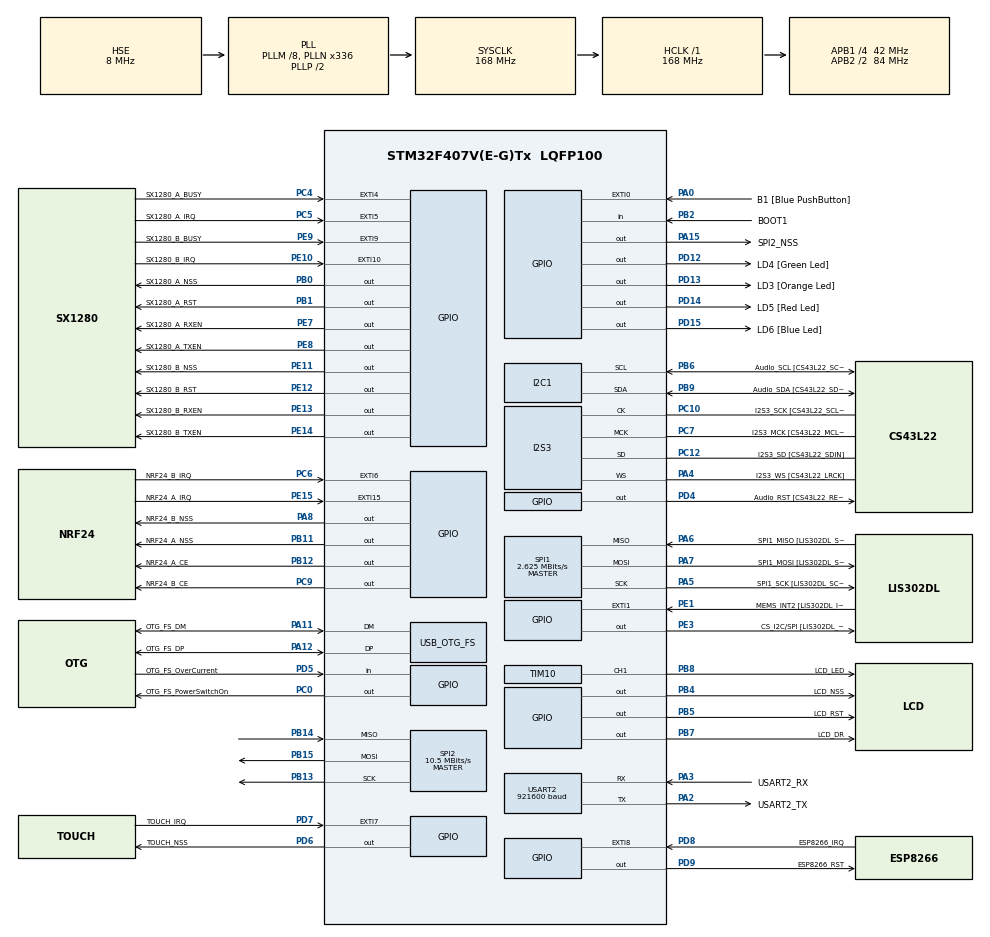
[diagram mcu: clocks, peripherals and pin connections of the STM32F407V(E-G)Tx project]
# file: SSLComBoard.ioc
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Dma.Request0=SPI2_RX
Dma.Request1=SPI2_TX
Dma.Request2=SPI1_RX
Dma.Request3=SPI1_TX
Dma.Request4=USART2_RX
Dma.Request5=USART2_TX
Dma.SPI1_RX.2.Direction=DMA_PERIPH_TO_MEMORY
Dma.SPI1_RX.2.FIFOMode=DMA_FIFOMODE_DISABLE
Dma.SPI1_RX.2.Instance=DMA2_Stream0
Dma.SPI1_RX.2.MemDataAlignment=DMA_MDATAALIGN_BYTE
Dma.SPI1_RX.2.MemInc=DMA_MINC_ENABLE
Dma.SPI1_RX.2.Mode=DMA_NORMAL
Dma.SPI1_RX.2.PeriphDataAlignment=DMA_PDATAALIGN_BYTE
Dma.SPI1_RX.2.PeriphInc=DMA_PINC_DISABLE
Dma.SPI1_RX.2.Priority=DMA_PRIORITY_LOW
Dma.SPI1_TX.3.Direction=DMA_MEMORY_TO_PERIPH
Dma.SPI1_TX.3.FIFOMode=DMA_FIFOMODE_DISABLE
Dma.SPI1_TX.3.Instance=DMA2_Stream3
Dma.SPI1_TX.3.MemDataAlignment=DMA_MDATAALIGN_BYTE
Dma.SPI1_TX.3.MemInc=DMA_MINC_ENABLE
Dma.SPI1_TX.3.Mode=DMA_NORMAL
Dma.SPI1_TX.3.PeriphDataAlignment=DMA_PDATAALIGN_BYTE
Dma.SPI1_TX.3.PeriphInc=DMA_PINC_DISABLE
Dma.SPI1_TX.3.Priority=DMA_PRIORITY_LOW
Dma.SPI2_RX.0.Direction=DMA_PERIPH_TO_MEMORY
Dma.SPI2_RX.0.FIFOMode=DMA_FIFOMODE_DISABLE
Dma.SPI2_RX.0.Instance=DMA1_Stream3
Dma.SPI2_RX.0.MemDataAlignment=DMA_MDATAALIGN_BYTE
Dma.SPI2_RX.0.MemInc=DMA_MINC_ENABLE
Dma.SPI2_RX.0.Mode=DMA_NORMAL
Dma.SPI2_RX.0.PeriphDataAlignment=DMA_PDATAALIGN_BYTE
Dma.SPI2_RX.0.PeriphInc=DMA_PINC_DISABLE
Dma.SPI2_RX.0.Priority=DMA_PRIORITY_LOW
Dma.SPI2_TX.1.Direction=DMA_MEMORY_TO_PERIPH
Dma.SPI2_TX.1.FIFOMode=DMA_FIFOMODE_DISABLE
Dma.SPI2_TX.1.Instance=DMA1_Stream4
Dma.SPI2_TX.1.MemDataAlignment=DMA_MDATAALIGN_BYTE
Dma.SPI2_TX.1.MemInc=DMA_MINC_ENABLE
Dma.SPI2_TX.1.Mode=DMA_NORMAL
Dma.SPI2_TX.1.PeriphDataAlignment=DMA_PDATAALIGN_BYTE
Dma.SPI2_TX.1.PeriphInc=DMA_PINC_DISABLE
Dma.SPI2_TX.1.Priority=DMA_PRIORITY_LOW
Dma.USART2_RX.4.Direction=DMA_PERIPH_TO_MEMORY
Dma.USART2_RX.4.FIFOMode=DMA_FIFOMODE_DISABLE
Dma.USART2_RX.4.Instance=DMA1_Stream5
Dma.USART2_RX.4.MemDataAlignment=DMA_MDATAALIGN_BYTE
Dma.USART2_RX.4.MemInc=DMA_MINC_ENABLE
Dma.USART2_RX.4.Mode=DMA_NORMAL
Dma.USART2_RX.4.PeriphDataAlignment=DMA_PDATAALIGN_BYTE
Dma.USART2_RX.4.PeriphInc=DMA_PINC_DISABLE
Dma.USART2_RX.4.Priority=DMA_PRIORITY_LOW
Dma.USART2_TX.5.Direction=DMA_MEMORY_TO_PERIPH
Dma.USART2_TX.5.FIFOMode=DMA_FIFOMODE_DISABLE
Dma.USART2_TX.5.Instance=DMA1_Stream6
Dma.USART2_TX.5.MemDataAlignment=DMA_MDATAALIGN_BYTE
Dma.USART2_TX.5.MemInc=DMA_MINC_ENABLE
Dma.USART2_TX.5.Mode=DMA_NORMAL
Dma.USART2_TX.5.PeriphDataAlignment=DMA_PDATAALIGN_BYTE
Dma.USART2_TX.5.PeriphInc=DMA_PINC_DISABLE
Dma.USART2_TX.5.Priority=DMA_PRIORITY_LOW
FREERTOS.Tasks01=defaultTask,24,512,StartDefaultTask,Default,NULL,Dynamic,NULL,NULL
FREERTOS.configENABLE_FPU=1
FREERTOS.configRECORD_STACK_HIGH_ADDRESS=1
FREERTOS.configTIMER_TASK_PRIORITY=48
FREERTOS.configUSE_NEWLIB_REENTRANT=1
I2S3.AudioFreq-Half_Duplex_Master=I2S_AUDIOFREQ_96K
I2S3.ErrorAudioFreq=-2.34 %
I2S3.ErrorAudioFreq-Half_Duplex_Master=0.8 %
I2S3.FullDuplexMode=I2S_FULLDUPLEXMODE_DISABLE
I2S3.Instance=SPI$Index
I2S3.RealAudioFreq=93.75 KHz
I2S3.RealAudioFreq-Half_Duplex_Master=96.774 KHz
I2S3.VirtualMode=I2S_MODE_MASTER
Mcu.Family=STM32F4
Mcu.Name=STM32F407V(E-G)Tx
Mcu.Package=LQFP100
NVIC.DMA1_Stream3_IRQn=true\:5\:0\:false\:false\:true\:true\:false\:true\:true
NVIC.DMA1_Stream4_IRQn=true\:5\:0\:false\:false\:true\:true\:false\:true\:true
NVIC.DMA1_Stream5_IRQn=true\:5\:0\:false\:false\:true\:true\:false\:true\:true
NVIC.DMA1_Stream6_IRQn=true\:5\:0\:false\:false\:true\:true\:false\:true\:true
NVIC.DMA2_Stream0_IRQn=true\:5\:0\:false\:false\:true\:true\:false\:true\:true
NVIC.DMA2_Stream3_IRQn=true\:5\:0\:false\:false\:true\:true\:false\:true\:true
NVIC.EXTI0_IRQn=true\:5\:0\:false\:false\:true\:true\:true\:true\:true
NVIC.EXTI15_10_IRQn=true\:5\:0\:false\:false\:true\:true\:true\:true\:true
NVIC.EXTI4_IRQn=true\:5\:0\:false\:false\:true\:true\:true\:true\:true
NVIC.EXTI9_5_IRQn=true\:5\:0\:false\:false\:true\:true\:true\:true\:true
NVIC.PriorityGroup=NVIC_PRIORITYGROUP_4
NVIC.TIM7_IRQn=true\:15\:0\:false\:false\:true\:false\:false\:true\:true
NVIC.TimeBase=TIM7_IRQn
NVIC.TimeBaseIP=TIM7
NVIC.USART2_IRQn=true\:5\:0\:false\:false\:true\:true\:true\:true\:true
PA0-WKUP.GPIO_Label=B1 [Blue PushButton]
PA0-WKUP.GPIO_ModeDefaultEXTI=GPIO_MODE_IT_RISING
PA0-WKUP.GPIO_PuPd=GPIO_PULLDOWN
PA0-WKUP.Signal=GPXTI0
PA10.GPIO_Label=OTG_FS_ID
PA10.GPIO_Mode=GPIO_MODE_AF_PP
PA10.GPIO_PuPd=GPIO_NOPULL
PA10.GPIO_Speed=GPIO_SPEED_FREQ_LOW
PA10.Signal=USB_OTG_FS_ID
PA11.GPIO_Label=OTG_FS_DM
PA11.GPIO_Mode=GPIO_MODE_AF_PP
PA11.GPIO_PuPd=GPIO_NOPULL
PA11.GPIO_Speed=GPIO_SPEED_FREQ_LOW
PA11.Mode=Device_Only
PA11.Signal=USB_OTG_FS_DM
PA12.GPIO_Label=OTG_FS_DP
PA12.GPIO_Mode=GPIO_MODE_AF_PP
PA12.GPIO_PuPd=GPIO_NOPULL
PA12.GPIO_Speed=GPIO_SPEED_FREQ_LOW
PA12.Mode=Device_Only
PA12.Signal=USB_OTG_FS_DP
PA13.GPIO_Label=SWDIO
PA13.Mode=Trace_Asynchronous_SW
PA13.Signal=SYS_JTMS-SWDIO
PA14.GPIO_Label=SWCLK
PA14.Mode=Trace_Asynchronous_SW
PA14.Signal=SYS_JTCK-SWCLK
PA15.GPIO_Label=SPI2_NSS
PA15.PinState=GPIO_PIN_SET
PA15.Signal=GPIO_Output
PA2.GPIO_Label=USART2_TX
PA2.Mode=Asynchronous
PA2.Signal=USART2_TX
PA3.GPIO_Label=USART2_RX
PA3.Mode=Asynchronous
PA3.Signal=USART2_RX
PA4.GPIO_Label=I2S3_WS [CS43L22_LRCK]
PA4.GPIO_Mode=GPIO_MODE_AF_PP
PA4.GPIO_PuPd=GPIO_NOPULL
PA4.GPIO_Speed=GPIO_SPEED_FREQ_LOW
PA4.Mode=Half_Duplex_Master
PA4.Signal=I2S3_WS
PA5.GPIO_Label=SPI1_SCK [LIS302DL_SCL/SPC]
PA5.GPIO_Mode=GPIO_MODE_AF_PP
PA5.GPIO_PuPd=GPIO_NOPULL
PA5.GPIO_Speed=GPIO_SPEED_FREQ_VERY_HIGH
PA5.Mode=Full_Duplex_Master
PA5.Signal=SPI1_SCK
PA6.GPIO_Label=SPI1_MISO [LIS302DL_SDO]
PA6.GPIO_Mode=GPIO_MODE_AF_PP
PA6.GPIO_PuPd=GPIO_NOPULL
PA6.GPIO_Speed=GPIO_SPEED_FREQ_VERY_HIGH
PA6.Mode=Full_Duplex_Master
PA6.Signal=SPI1_MISO
PA7.GPIO_Label=SPI1_MOSI [LIS302DL_SDA/SDI/SDO]
PA7.GPIO_Mode=GPIO_MODE_AF_PP
PA7.GPIO_PuPd=GPIO_NOPULL
PA7.GPIO_Speed=GPIO_SPEED_FREQ_VERY_HIGH
PA7.Mode=Full_Duplex_Master
PA7.Signal=SPI1_MOSI
PA8.GPIO_Label=NRF24_B_NSS
PA8.PinState=GPIO_PIN_SET
PA8.Signal=GPIO_Output
PA9.GPIO_Label=VBUS_FS
PA9.GPIO_Mode=GPIO_MODE_INPUT
PA9.GPIO_PuPd=GPIO_NOPULL
PA9.Signal=USB_OTG_FS_VBUS
PB0.GPIO_Label=SX1280_A_NSS
PB0.PinState=GPIO_PIN_SET
PB0.Signal=GPIO_Output
PB1.GPIO_Label=SX1280_A_RST
PB1.Signal=GPIO_Output
PB10.GPIO_Label=CLK_IN [MP45DT02_CLK]
PB10.GPIO_Mode=GPIO_MODE_AF_PP
PB10.GPIO_PuPd=GPIO_NOPULL
PB10.GPIO_Speed=GPIO_SPEED_FREQ_LOW
PB10.Signal=I2S2_CK
PB11.GPIO_Label=NRF24_A_NSS
PB11.PinState=GPIO_PIN_SET
PB11.Signal=GPIO_Output
PB12.GPIO_Label=NRF24_A_CE
PB12.Signal=GPIO_Output
PB13.Mode=Full_Duplex_Master
PB13.Signal=SPI2_SCK
PB14.Mode=Full_Duplex_Master
PB14.Signal=SPI2_MISO
PB15.Mode=Full_Duplex_Master
PB15.Signal=SPI2_MOSI
PB2.GPIO_Label=BOOT1
PB2.GPIO_Mode=GPIO_MODE_INPUT
PB2.GPIO_PuPd=GPIO_NOPULL
PB2.Signal=GPIO_Input
PB3.GPIO_Label=SWO
PB3.Mode=Trace_Asynchronous_SW
PB3.Signal=SYS_JTDO-SWO
PB4.GPIO_Label=LCD_NSS
PB4.PinState=GPIO_PIN_SET
PB4.Signal=GPIO_Output
PB5.GPIO_Label=LCD_RST
PB5.Signal=GPIO_Output
PB6.GPIO_Label=Audio_SCL [CS43L22_SCL]
PB6.GPIO_Mode=GPIO_MODE_AF_OD
PB6.GPIO_Pu=GPIO_PULLUP
PB6.GPIO_PuPd=GPIO_NOPULL
PB6.GPIO_Speed=GPIO_SPEED_FREQ_LOW
PB6.Mode=I2C
PB6.Signal=I2C1_SCL
PB7.GPIO_Label=LCD_DR
PB7.Signal=GPIO_Output
PB8.GPIO_Label=LCD_LED
PB8.Signal=S_TIM10_CH1
PB9.GPIO_Label=Audio_SDA [CS43L22_SDA]
PB9.GPIO_Mode=GPIO_MODE_AF_OD
PB9.GPIO_Pu=GPIO_PULLUP
PB9.GPIO_PuPd=GPIO_NOPULL
PB9.GPIO_Speed=GPIO_SPEED_FREQ_LOW
PB9.Mode=I2C
PB9.Signal=I2C1_SDA
PC0.GPIO_Label=OTG_FS_PowerSwitchOn
PC0.GPIO_PuPd=GPIO_NOPULL
PC0.GPIO_Speed=GPIO_SPEED_FREQ_LOW
PC0.PinState=GPIO_PIN_SET
PC0.Signal=GPIO_Output
PC10.GPIO_Label=I2S3_SCK [CS43L22_SCLK]
PC10.GPIO_Mode=GPIO_MODE_AF_PP
PC10.GPIO_PuPd=GPIO_NOPULL
PC10.GPIO_Speed=GPIO_SPEED_FREQ_LOW
PC10.Mode=Half_Duplex_Master
PC10.Signal=I2S3_CK
PC12.GPIO_Label=I2S3_SD [CS43L22_SDIN]
PC12.GPIO_Mode=GPIO_MODE_AF_PP
PC12.GPIO_PuPd=GPIO_NOPULL
PC12.GPIO_Speed=GPIO_SPEED_FREQ_LOW
PC12.Mode=Half_Duplex_Master
PC12.Signal=I2S3_SD
PC14-OSC32_IN.GPIO_Label=PC14-OSC32_IN
PC14-OSC32_IN.Mode=LSE-External-Oscillator
PC14-OSC32_IN.Signal=RCC_OSC32_IN
PC15-OSC32_OUT.GPIO_Label=PC15-OSC32_OUT
PC15-OSC32_OUT.Mode=LSE-External-Oscillator
PC15-OSC32_OUT.Signal=RCC_OSC32_OUT
PC3.GPIO_Label=PDM_OUT [MP45DT02_DOUT]
PC3.GPIO_Mode=GPIO_MODE_AF_PP
PC3.GPIO_PuPd=GPIO_NOPULL
PC3.GPIO_Speed=GPIO_SPEED_FREQ_LOW
PC3.Signal=I2S2_SD
PC4.GPIO_Label=SX1280_A_BUSY
PC4.GPIO_PuPd=GPIO_PULLDOWN
PC4.Signal=GPXTI4
PC5.GPIO_Label=SX1280_A_IRQ
PC5.GPIO_PuPd=GPIO_PULLDOWN
PC5.Signal=GPXTI5
PC6.GPIO_Label=NRF24_B_IRQ
PC6.GPIO_PuPd=GPIO_PULLDOWN
PC6.Signal=GPXTI6
PC7.GPIO_Label=I2S3_MCK [CS43L22_MCLK]
PC7.GPIO_Mode=GPIO_MODE_AF_PP
PC7.GPIO_PuPd=GPIO_NOPULL
PC7.GPIO_Speed=GPIO_SPEED_FREQ_LOW
PC7.Mode=Master_Clock_Activated
PC7.Signal=I2S3_MCK
PC9.GPIO_Label=NRF24_B_CE
PC9.Signal=GPIO_Output
PD12.GPIO_Label=LD4 [Green Led]
PD12.GPIO_PuPd=GPIO_NOPULL
PD12.GPIO_Speed=GPIO_SPEED_FREQ_LOW
PD12.Signal=GPIO_Output
PD13.GPIO_Label=LD3 [Orange Led]
PD13.GPIO_PuPd=GPIO_NOPULL
PD13.GPIO_Speed=GPIO_SPEED_FREQ_LOW
PD13.Signal=GPIO_Output
PD14.GPIO_Label=LD5 [Red Led]
PD14.GPIO_PuPd=GPIO_NOPULL
PD14.GPIO_Speed=GPIO_SPEED_FREQ_LOW
PD14.Signal=GPIO_Output
PD15.GPIO_Label=LD6 [Blue Led]
PD15.GPIO_PuPd=GPIO_NOPULL
PD15.GPIO_Speed=GPIO_SPEED_FREQ_LOW
PD15.Signal=GPIO_Output
PD4.GPIO_Label=Audio_RST [CS43L22_RESET]
PD4.GPIO_PuPd=GPIO_NOPULL
PD4.GPIO_Speed=GPIO_SPEED_FREQ_LOW
PD4.Signal=GPIO_Output
PD5.GPIO_Label=OTG_FS_OverCurrent
PD5.GPIO_Mode=GPIO_MODE_INPUT
PD5.GPIO_PuPd=GPIO_NOPULL
PD5.Signal=GPIO_Input
PD6.GPIO_Label=TOUCH_NSS
PD6.PinState=GPIO_PIN_SET
PD6.Signal=GPIO_Output
PD7.GPIO_Label=TOUCH_IRQ
PD7.GPIO_PuPd=GPIO_PULLDOWN
PD7.Signal=GPXTI7
PD8.GPIO_Label=ESP8266_IRQ
PD8.GPIO_ModeDefaultEXTI=GPIO_MODE_IT_FALLING
PD8.GPIO_PuPd=GPIO_PULLUP
PD8.Signal=GPXTI8
PD9.GPIO_Label=ESP8266_RST
PD9.Signal=GPIO_Output
PE1.GPIO_Label=MEMS_INT2 [LIS302DL_INT2]
PE1.GPIO_ModeDefaultEXTI=GPIO_MODE_EVT_RISING
PE1.GPIO_PuPd=GPIO_PULLDOWN
PE1.Signal=GPXTI1
PE10.GPIO_Label=SX1280_B_IRQ
PE10.GPIO_PuPd=GPIO_PULLDOWN
PE10.Signal=GPXTI10
PE11.GPIO_Label=SX1280_B_NSS
PE11.PinState=GPIO_PIN_SET
PE11.Signal=GPIO_Output
PE12.GPIO_Label=SX1280_B_RST
PE12.Signal=GPIO_Output
PE13.GPIO_Label=SX1280_B_RXEN
PE13.PinState=GPIO_PIN_SET
PE13.Signal=GPIO_Output
PE14.GPIO_Label=SX1280_B_TXEN
PE14.Signal=GPIO_Output
PE15.GPIO_Label=NRF24_A_IRQ
PE15.GPIO_PuPd=GPIO_PULLDOWN
PE15.Signal=GPXTI15
PE3.GPIO_Label=CS_I2C/SPI [LIS302DL_CS_I2C/SPI]
PE3.GPIO_PuPd=GPIO_NOPULL
PE3.GPIO_Speed=GPIO_SPEED_FREQ_LOW
PE3.PinState=GPIO_PIN_SET
PE3.Signal=GPIO_Output
PE7.GPIO_Label=SX1280_A_RXEN
PE7.PinState=GPIO_PIN_SET
PE7.Signal=GPIO_Output
PE8.GPIO_Label=SX1280_A_TXEN
PE8.Signal=GPIO_Output
PE9.GPIO_Label=SX1280_B_BUSY
PE9.GPIO_PuPd=GPIO_PULLDOWN
PE9.Signal=GPXTI9
PH0-OSC_IN.GPIO_Label=PH0-OSC_IN
PH0-OSC_IN.Mode=HSE-External-Oscillator
PH0-OSC_IN.Signal=RCC_OSC_IN
PH1-OSC_OUT.GPIO_Label=PH1-OSC_OUT
PH1-OSC_OUT.Mode=HSE-External-Oscillator
PH1-OSC_OUT.Signal=RCC_OSC_OUT
ProjectManager.HeapSize=0x200
ProjectManager.StackSize=0x400
ProjectManager.TargetToolchain=STM32CubeIDE
RCC.48MHZClocksFreq_Value=48000000
RCC.AHBFreq_Value=168000000
RCC.APB1CLKDivider=RCC_HCLK_DIV4
RCC.APB1Freq_Value=42000000
RCC.APB1TimFreq_Value=84000000
RCC.APB2CLKDivider=RCC_HCLK_DIV2
RCC.APB2Freq_Value=84000000
RCC.APB2TimFreq_Value=168000000
RCC.CortexFreq_Value=168000000
RCC.HCLKFreq_Value=168000000
RCC.HSE_VALUE=8000000
RCC.HSI_VALUE=16000000
RCC.PLLM=8
RCC.PLLN=336
RCC.PLLQ=7
RCC.SYSCLKFreq_VALUE=168000000
RCC.SYSCLKSource=RCC_SYSCLKSOURCE_PLLCLK
RCC.VCOOutputFreq_Value=336000000
SH.S_TIM10_CH1.0=TIM10_CH1,PWM Generation1 CH1
SPI1.BaudRatePrescaler=SPI_BAUDRATEPRESCALER_32
SPI1.BaudRatePrescaler-Full_Duplex_Master=SPI_BAUDRATEPRESCALER_2
SPI1.CLKPhase=SPI_PHASE_1EDGE
SPI1.CalculateBaudRate=2.625 MBits/s
SPI1.CalculateBaudRate-Full_Duplex_Master=42.0 MBits/s
SPI1.Direction=SPI_DIRECTION_2LINES
SPI1.Mode=SPI_MODE_MASTER
SPI1.Mode-Full_Duplex_Master=SPI_MODE_MASTER
SPI1.VirtualType=VM_MASTER
SPI2.BaudRatePrescaler=SPI_BAUDRATEPRESCALER_4
SPI2.CalculateBaudRate=10.5 MBits/s
SPI2.Direction=SPI_DIRECTION_2LINES
SPI2.Mode=SPI_MODE_MASTER
SPI2.VirtualType=VM_MASTER
TIM10.Channel=TIM_CHANNEL_1
USART2.BaudRate=921600
USART2.VirtualMode=VM_ASYNC
USB_OTG_FS.VirtualMode=Device_Only
VP_FREERTOS_VS_CMSIS_V2.Mode=CMSIS_V2
VP_SYS_VS_tim7.Mode=TIM7
VP_TIM10_VS_ClockSourceINT.Mode=Enable_Timer
board=STM32F407G-DISC1

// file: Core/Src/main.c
/* USER CODE BEGIN Header */
/**
  ******************************************************************************
  * @file           : main.c
  * @brief          : Main program body
  ******************************************************************************
  * @attention
  *
  * Copyright (c) 2024 STMicroelectronics.
  * All rights reserved.
  *
  * This software is licensed under terms that can be found in the LICENSE file
  * in the root directory of this software component.
  * If no LICENSE file comes with this software, it is provided AS-IS.
  *
  ******************************************************************************
  */
/* USER CODE END Header */
#include "main.h"
#include "cmsis_os.h"
#include "dma.h"
#include "i2c.h"
#include "i2s.h"
#include "spi.h"
#include "tim.h"
#include "usart.h"
#include "usb_otg.h"
#include "gpio.h"

void SystemClock_Config(void);
void MX_FREERTOS_Init(void);

int main(void)
{

  /* MCU Configuration--------------------------------------------------------*/

  /* Reset of all peripherals, Initializes the Flash interface and the Systick. */
  HAL_Init();

  /* Configure the system clock */
  SystemClock_Config();

  /* Initialize all configured peripherals */
  MX_GPIO_Init();
  MX_DMA_Init();
  MX_I2C1_Init();
  MX_I2S3_Init();
  MX_SPI1_Init();
  MX_SPI2_Init();
  MX_TIM10_Init();
  MX_USART2_UART_Init();
  MX_USB_OTG_FS_PCD_Init();

  /* Init scheduler */
  osKernelInitialize();

  /* Call init function for freertos objects (in cmsis_os2.c) */
  MX_FREERTOS_Init();

  /* Start scheduler */
  osKernelStart();

  /* We should never get here as control is now taken by the scheduler */

  /* Infinite loop */
  while (1)
  {

  }
}

void SystemClock_Config(void)
{
  RCC_OscInitTypeDef RCC_OscInitStruct = {0};
  RCC_ClkInitTypeDef RCC_ClkInitStruct = {0};

  /** Configure the main internal regulator output voltage
  */
  __HAL_RCC_PWR_CLK_ENABLE();
  __HAL_PWR_VOLTAGESCALING_CONFIG(PWR_REGULATOR_VOLTAGE_SCALE1);

  /** Initializes the RCC Oscillators according to the specified parameters
  * in the RCC_OscInitTypeDef structure.
  */
  RCC_OscInitStruct.OscillatorType = RCC_OSCILLATORTYPE_HSE;
  RCC_OscInitStruct.HSEState = RCC_HSE_ON;
  RCC_OscInitStruct.PLL.PLLState = RCC_PLL_ON;
  RCC_OscInitStruct.PLL.PLLSource = RCC_PLLSOURCE_HSE;
  RCC_OscInitStruct.PLL.PLLM = 8;
  RCC_OscInitStruct.PLL.PLLN = 336;
  RCC_OscInitStruct.PLL.PLLP = RCC_PLLP_DIV2;
  RCC_OscInitStruct.PLL.PLLQ = 7;
  if (HAL_RCC_OscConfig(&RCC_OscInitStruct) != HAL_OK)
  {
    Error_Handler();
  }

  /** Initializes the CPU, AHB and APB buses clocks
  */
  RCC_ClkInitStruct.ClockType = RCC_CLOCKTYPE_HCLK|RCC_CLOCKTYPE_SYSCLK
                              |RCC_CLOCKTYPE_PCLK1|RCC_CLOCKTYPE_PCLK2;
  RCC_ClkInitStruct.SYSCLKSource = RCC_SYSCLKSOURCE_PLLCLK;
  RCC_ClkInitStruct.AHBCLKDivider = RCC_SYSCLK_DIV1;
  RCC_ClkInitStruct.APB1CLKDivider = RCC_HCLK_DIV4;
  RCC_ClkInitStruct.APB2CLKDivider = RCC_HCLK_DIV2;

  if (HAL_RCC_ClockConfig(&RCC_ClkInitStruct, FLASH_LATENCY_5) != HAL_OK)
  {
    Error_Handler();
  }
}

void HAL_TIM_PeriodElapsedCallback(TIM_HandleTypeDef *htim)
{
  if (htim->Instance == TIM7) {
    HAL_IncTick();
  }
}

void Error_Handler(void)
{
  __disable_irq();
  while (1)
  {
  }
}

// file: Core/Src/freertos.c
/* USER CODE BEGIN Header */
/**
  ******************************************************************************
  * File Name          : freertos.c
  * Description        : Code for freertos applications
  ******************************************************************************
  * @attention
  *
  * Copyright (c) 2024 STMicroelectronics.
  * All rights reserved.
  *
  * This software is licensed under terms that can be found in the LICENSE file
  * in the root directory of this software component.
  * If no LICENSE file comes with this software, it is provided AS-IS.
  *
  ******************************************************************************
  */
/* USER CODE END Header */

#include "FreeRTOS.h"
#include "task.h"
#include "main.h"
#include "cmsis_os.h"

/* USER CODE BEGIN Includes */
#include "../../Application/start.h"
/* USER CODE END Includes */

/* Definitions for defaultTask */
osThreadId_t defaultTaskHandle;
const osThreadAttr_t defaultTask_attributes = {
  .name = "defaultTask",
  .stack_size = 512 * 4,
  .priority = (osPriority_t) osPriorityNormal,
};

void StartDefaultTask(void *argument);

void MX_FREERTOS_Init(void); /* (MISRA C 2004 rule 8.1) */

void MX_FREERTOS_Init(void) {

  /* Create the thread(s) */
  /* creation of defaultTask */
  defaultTaskHandle = osThreadNew(StartDefaultTask, NULL, &defaultTask_attributes);

}

void StartDefaultTask(void *argument)
{
  /* USER CODE BEGIN StartDefaultTask */
  start();
  /* Infinite loop */
  for(;;)
  {
    osDelay(1);
  }
  /* USER CODE END StartDefaultTask */
}
